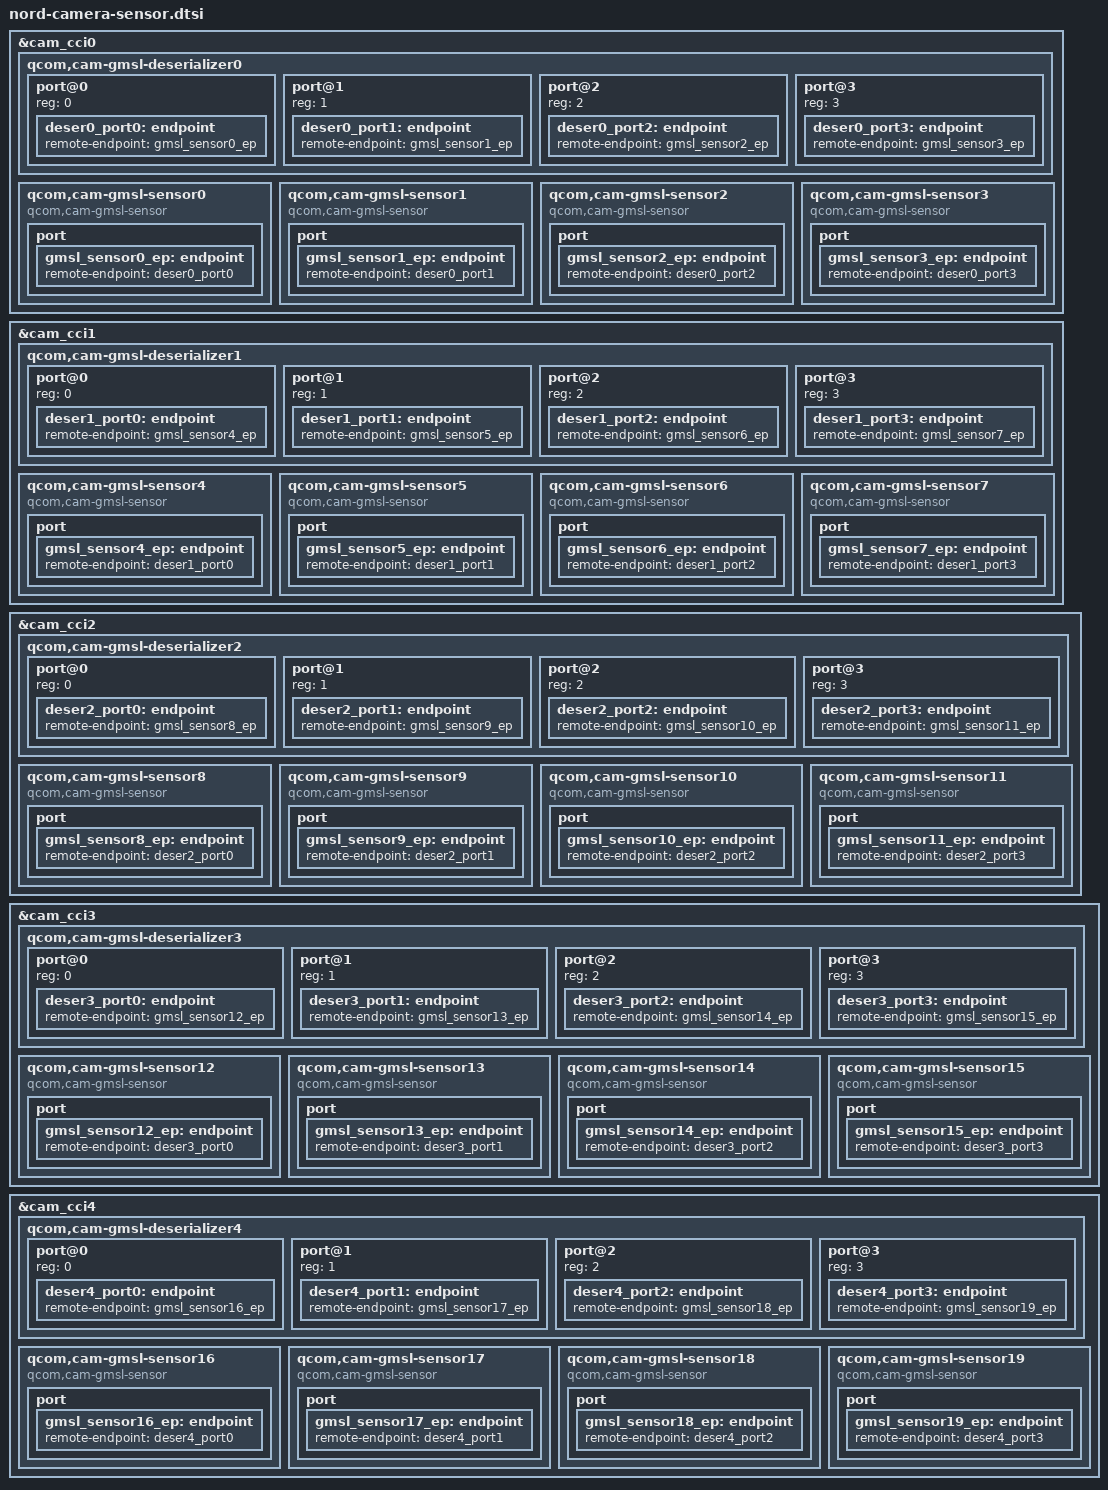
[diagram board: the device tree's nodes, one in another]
// SPDX-License-Identifier: BSD-3-Clause
/*
 * Copyright (c) Qualcomm Technologies, Inc. and/or its subsidiaries.
 */

#include <dt-bindings/camera/msm-camera.h>

&cam_cci0 {
	/* GMSL deserializer 0 */
	qcom,cam-gmsl-deserializer0 {
		cell-index = <0>;
		csiphy-sd-index = <0>;
		sensor-position-roll = <0>;
		sensor-position-pitch = <0>;
		sensor-position-yaw = <180>;
		cam_vio-supply = <&vreg_l8a_1p8>;
		regulator-names = "cam_vio";
		power-domains = <&camcc CAM_CC_TITAN_TOP_GDSC>;
		rgltr-cntrl-support;
		pwm-switch;
		rgltr-min-voltage = <1800000>;
		rgltr-max-voltage = <1800000>;
		rgltr-load-current = <120000>;
		gpio-no-mux = <0>;
		gpios = <&pmic_h_gpios 5 0>;
		gpio-reset = <0>;
		gpio-req-tbl-num = <0>;
		gpio-req-tbl-flags = <0>;
		gpio-req-tbl-label = "CAM_RESET0";
		cci-master = <0>;
		status = "ok";
		#address-cells = <1>;
		#size-cells = <0>;

		port@0 {
			reg = <0>;

			deser0_port0: endpoint {
				remote-endpoint = <&gmsl_sensor0_ep>;
			};
		};

		port@1 {
			reg = <1>;

			deser0_port1: endpoint {
				remote-endpoint = <&gmsl_sensor1_ep>;
			};
		};

		port@2 {
			reg = <2>;

			deser0_port2: endpoint {
				remote-endpoint = <&gmsl_sensor2_ep>;
			};
		};

		port@3 {
			reg = <3>;

			deser0_port3: endpoint {
				remote-endpoint = <&gmsl_sensor3_ep>;
			};
		};
	};

	/* GMSL deserializer 0 sensor 0 */
	qcom,cam-gmsl-sensor0 {
		compatible = "qcom,cam-gmsl-sensor";
		cell-index = <0>;
		csiphy-sd-index = <0>;
		status = "ok";

		port {
			gmsl_sensor0_ep: endpoint {
				remote-endpoint = <&deser0_port0>;
			};
		};
	};

	/* GMSL deserializer 0 sensor 1 */
	qcom,cam-gmsl-sensor1 {
		compatible = "qcom,cam-gmsl-sensor";
		cell-index = <1>;
		csiphy-sd-index = <0>;
		status = "ok";

		port {
			gmsl_sensor1_ep: endpoint {
				remote-endpoint = <&deser0_port1>;
			};
		};
	};

	/* GMSL deserializer 0 sensor 2 */
	qcom,cam-gmsl-sensor2 {
		compatible = "qcom,cam-gmsl-sensor";
		cell-index = <2>;
		csiphy-sd-index = <0>;
		status = "ok";

		port {
			gmsl_sensor2_ep: endpoint {
				remote-endpoint = <&deser0_port2>;
			};
		};
	};

	/* GMSL deserializer 0 sensor 3 */
	qcom,cam-gmsl-sensor3 {
		compatible = "qcom,cam-gmsl-sensor";
		cell-index = <3>;
		csiphy-sd-index = <0>;
		status = "ok";

		port {
			gmsl_sensor3_ep: endpoint {
				remote-endpoint = <&deser0_port3>;
			};
		};
	};
};

&cam_cci1 {
	/* GMSL deserializer 1 */
	qcom,cam-gmsl-deserializer1 {
		cell-index = <1>;
		csiphy-sd-index = <1>;
		sensor-position-roll = <0>;
		sensor-position-pitch = <0>;
		sensor-position-yaw = <180>;
		cam_vio-supply = <&vreg_l8a_1p8>;
		regulator-names = "cam_vio";
		power-domains = <&camcc CAM_CC_TITAN_TOP_GDSC>;
		rgltr-cntrl-support;
		pwm-switch;
		rgltr-min-voltage = <1800000>;
		rgltr-max-voltage = <1800000>;
		rgltr-load-current = <120000>;
		gpio-no-mux = <0>;
		gpios = <&pmic_h_gpios 6 0>;
		gpio-reset = <0>;
		gpio-req-tbl-num = <0>;
		gpio-req-tbl-flags = <0>;
		gpio-req-tbl-label = "CAM_RESET1";
		cci-master = <0>;
		status = "ok";
		#address-cells = <1>;
		#size-cells = <0>;

		port@0 {
			reg = <0>;

			deser1_port0: endpoint {
				remote-endpoint = <&gmsl_sensor4_ep>;
			};
		};

		port@1 {
			reg = <1>;

			deser1_port1: endpoint {
				remote-endpoint = <&gmsl_sensor5_ep>;
			};
		};

		port@2 {
			reg = <2>;

			deser1_port2: endpoint {
				remote-endpoint = <&gmsl_sensor6_ep>;
			};
		};

		port@3 {
			reg = <3>;

			deser1_port3: endpoint {
				remote-endpoint = <&gmsl_sensor7_ep>;
			};
		};
	};

	/* GMSL deserializer 1 sensor 0 */
	qcom,cam-gmsl-sensor4 {
		compatible = "qcom,cam-gmsl-sensor";
		cell-index = <4>;
		csiphy-sd-index = <1>;
		status = "ok";

		port {
			gmsl_sensor4_ep: endpoint {
				remote-endpoint = <&deser1_port0>;
			};
		};
	};

	/* GMSL deserializer 1 sensor 1 */
	qcom,cam-gmsl-sensor5 {
		compatible = "qcom,cam-gmsl-sensor";
		cell-index = <5>;
		csiphy-sd-index = <1>;
		status = "ok";

		port {
			gmsl_sensor5_ep: endpoint {
				remote-endpoint = <&deser1_port1>;
			};
		};
	};

	/* GMSL deserializer 1 sensor 2 */
	qcom,cam-gmsl-sensor6 {
		compatible = "qcom,cam-gmsl-sensor";
		cell-index = <6>;
		csiphy-sd-index = <1>;
		status = "ok";

		port {
			gmsl_sensor6_ep: endpoint {
				remote-endpoint = <&deser1_port2>;
			};
		};
	};

	/* GMSL deserializer 1 sensor 3 */
	qcom,cam-gmsl-sensor7 {
		compatible = "qcom,cam-gmsl-sensor";
		cell-index = <7>;
		csiphy-sd-index = <1>;
		status = "ok";

		port {
			gmsl_sensor7_ep: endpoint {
				remote-endpoint = <&deser1_port3>;
			};
		};
	};
};

&cam_cci2 {
	/* GMSL deserializer 2 */
	qcom,cam-gmsl-deserializer2 {
		cell-index = <2>;
		csiphy-sd-index = <2>;
		sensor-position-roll = <0>;
		sensor-position-pitch = <0>;
		sensor-position-yaw = <180>;
		cam_vio-supply = <&vreg_l8a_1p8>;
		regulator-names = "cam_vio";
		power-domains = <&camcc CAM_CC_TITAN_TOP_GDSC>;
		rgltr-cntrl-support;
		pwm-switch;
		rgltr-min-voltage = <1800000>;
		rgltr-max-voltage = <1800000>;
		rgltr-load-current = <120000>;
		gpio-no-mux = <0>;
		gpios = <&pmic_h_gpios 7 0>;
		gpio-reset = <0>;
		gpio-req-tbl-num = <0>;
		gpio-req-tbl-flags = <0>;
		gpio-req-tbl-label = "CAM_RESET2";
		cci-master = <0>;
		status = "ok";
		#address-cells = <1>;
		#size-cells = <0>;

		port@0 {
			reg = <0>;

			deser2_port0: endpoint {
				remote-endpoint = <&gmsl_sensor8_ep>;
			};
		};

		port@1 {
			reg = <1>;

			deser2_port1: endpoint {
				remote-endpoint = <&gmsl_sensor9_ep>;
			};
		};

		port@2 {
			reg = <2>;

			deser2_port2: endpoint {
				remote-endpoint = <&gmsl_sensor10_ep>;
			};
		};

		port@3 {
			reg = <3>;

			deser2_port3: endpoint {
				remote-endpoint = <&gmsl_sensor11_ep>;
			};
		};
	};

	/* GMSL deserializer 2 sensor 0 */
	qcom,cam-gmsl-sensor8 {
		compatible = "qcom,cam-gmsl-sensor";
		cell-index = <8>;
		csiphy-sd-index = <2>;
		status = "ok";

		port {
			gmsl_sensor8_ep: endpoint {
				remote-endpoint = <&deser2_port0>;
			};
		};
	};

	/* GMSL deserializer 2 sensor 1 */
	qcom,cam-gmsl-sensor9 {
		compatible = "qcom,cam-gmsl-sensor";
		cell-index = <9>;
		csiphy-sd-index = <2>;
		status = "ok";

		port {
			gmsl_sensor9_ep: endpoint {
				remote-endpoint = <&deser2_port1>;
			};
		};
	};

	/* GMSL deserializer 2 sensor 2 */
	qcom,cam-gmsl-sensor10 {
		compatible = "qcom,cam-gmsl-sensor";
		cell-index = <10>;
		csiphy-sd-index = <2>;
		status = "ok";

		port {
			gmsl_sensor10_ep: endpoint {
				remote-endpoint = <&deser2_port2>;
			};
		};
	};

	/* GMSL deserializer 2 sensor 3 */
	qcom,cam-gmsl-sensor11 {
		compatible = "qcom,cam-gmsl-sensor";
		cell-index = <11>;
		csiphy-sd-index = <2>;
		status = "ok";

		port {
			gmsl_sensor11_ep: endpoint {
				remote-endpoint = <&deser2_port3>;
			};
		};
	};
};

&cam_cci3 {
	/* GMSL deserializer 3 */
	qcom,cam-gmsl-deserializer3 {
		cell-index = <3>;
		csiphy-sd-index = <3>;
		sensor-position-roll = <0>;
		sensor-position-pitch = <0>;
		sensor-position-yaw = <180>;
		cam_vio-supply = <&vreg_l8a_1p8>;
		regulator-names = "cam_vio";
		power-domains = <&camcc CAM_CC_TITAN_TOP_GDSC>;
		rgltr-cntrl-support;
		pwm-switch;
		rgltr-min-voltage = <1800000>;
		rgltr-max-voltage = <1800000>;
		rgltr-load-current = <120000>;
		gpio-no-mux = <0>;
		gpios = <&pmic_h_gpios 8 0>;
		gpio-reset = <0>;
		gpio-req-tbl-num = <0>;
		gpio-req-tbl-flags = <0>;
		gpio-req-tbl-label = "CAM_RESET3";
		cci-master = <0>;
		status = "ok";
		#address-cells = <1>;
		#size-cells = <0>;

		port@0 {
			reg = <0>;

			deser3_port0: endpoint {
				remote-endpoint = <&gmsl_sensor12_ep>;
			};
		};

		port@1 {
			reg = <1>;

			deser3_port1: endpoint {
				remote-endpoint = <&gmsl_sensor13_ep>;
			};
		};

		port@2 {
			reg = <2>;

			deser3_port2: endpoint {
				remote-endpoint = <&gmsl_sensor14_ep>;
			};
		};

		port@3 {
			reg = <3>;

			deser3_port3: endpoint {
				remote-endpoint = <&gmsl_sensor15_ep>;
			};
		};
	};

	/* GMSL deserializer 3 sensor 0 */
	qcom,cam-gmsl-sensor12 {
		compatible = "qcom,cam-gmsl-sensor";
		cell-index = <12>;
		csiphy-sd-index = <3>;
		status = "ok";

		port {
			gmsl_sensor12_ep: endpoint {
				remote-endpoint = <&deser3_port0>;
			};
		};
	};

	/* GMSL deserializer 3 sensor 1 */
	qcom,cam-gmsl-sensor13 {
		compatible = "qcom,cam-gmsl-sensor";
		cell-index = <13>;
		csiphy-sd-index = <3>;
		status = "ok";

		port {
			gmsl_sensor13_ep: endpoint {
				remote-endpoint = <&deser3_port1>;
			};
		};
	};

	/* GMSL deserializer 3 sensor 2 */
	qcom,cam-gmsl-sensor14 {
		compatible = "qcom,cam-gmsl-sensor";
		cell-index = <14>;
		csiphy-sd-index = <3>;
		status = "ok";

		port {
			gmsl_sensor14_ep: endpoint {
				remote-endpoint = <&deser3_port2>;
			};
		};
	};

	/* GMSL deserializer 3 sensor 3 */
	qcom,cam-gmsl-sensor15 {
		compatible = "qcom,cam-gmsl-sensor";
		cell-index = <15>;
		csiphy-sd-index = <3>;
		status = "ok";

		port {
			gmsl_sensor15_ep: endpoint {
				remote-endpoint = <&deser3_port3>;
			};
		};
	};
};

&cam_cci4 {
	/* GMSL deserializer 4 */
	qcom,cam-gmsl-deserializer4 {
		cell-index = <4>;
		csiphy-sd-index = <4>;
		sensor-position-roll = <0>;
		sensor-position-pitch = <0>;
		sensor-position-yaw = <180>;
		cam_vio-supply = <&vreg_l8a_1p8>;
		regulator-names = "cam_vio";
		power-domains = <&camcc CAM_CC_TITAN_TOP_GDSC>;
		rgltr-cntrl-support;
		pwm-switch;
		rgltr-min-voltage = <1800000>;
		rgltr-max-voltage = <1800000>;
		rgltr-load-current = <120000>;
		gpio-no-mux = <0>;
		gpios = <&pmic_h_gpios 9 0>;
		gpio-reset = <0>;
		gpio-req-tbl-num = <0>;
		gpio-req-tbl-flags = <0>;
		gpio-req-tbl-label = "CAM_RESET4";
		cci-master = <0>;
		status = "ok";
		#address-cells = <1>;
		#size-cells = <0>;

		port@0 {
			reg = <0>;

			deser4_port0: endpoint {
				remote-endpoint = <&gmsl_sensor16_ep>;
			};
		};

		port@1 {
			reg = <1>;

			deser4_port1: endpoint {
				remote-endpoint = <&gmsl_sensor17_ep>;
			};
		};

		port@2 {
			reg = <2>;

			deser4_port2: endpoint {
				remote-endpoint = <&gmsl_sensor18_ep>;
			};
		};

		port@3 {
			reg = <3>;

			deser4_port3: endpoint {
				remote-endpoint = <&gmsl_sensor19_ep>;
			};
		};
	};

	/* GMSL deserializer 4 sensor 0 */
	qcom,cam-gmsl-sensor16 {
		compatible = "qcom,cam-gmsl-sensor";
		cell-index = <16>;
		csiphy-sd-index = <4>;
		status = "ok";

		port {
			gmsl_sensor16_ep: endpoint {
				remote-endpoint = <&deser4_port0>;
			};
		};
	};

	/* GMSL deserializer 4 sensor 1 */
	qcom,cam-gmsl-sensor17 {
		compatible = "qcom,cam-gmsl-sensor";
		cell-index = <17>;
		csiphy-sd-index = <4>;
		status = "ok";

		port {
			gmsl_sensor17_ep: endpoint {
				remote-endpoint = <&deser4_port1>;
			};
		};
	};

	/* GMSL deserializer 4 sensor 2 */
	qcom,cam-gmsl-sensor18 {
		compatible = "qcom,cam-gmsl-sensor";
		cell-index = <18>;
		csiphy-sd-index = <4>;
		status = "ok";

		port {
			gmsl_sensor18_ep: endpoint {
				remote-endpoint = <&deser4_port2>;
			};
		};
	};

	/* GMSL deserializer 4 sensor 3 */
	qcom,cam-gmsl-sensor19 {
		compatible = "qcom,cam-gmsl-sensor";
		cell-index = <19>;
		csiphy-sd-index = <4>;
		status = "ok";

		port {
			gmsl_sensor19_ep: endpoint {
				remote-endpoint = <&deser4_port3>;
			};
		};
	};
};
